# STM32L486xx register map
File version: 1.0
Registers are 32-bit, access not given, reset 0x0 unless marked. A register's access mark holds for its fields unless they carry their own. Offsets are from the block's base; [hi:lo] are bit positions.

## DAC
Base 0x40007400
0x00 CR
  [31] BWST2, [30] CEN2, [30] CAL_FLAG2, [29] DMAUDRIE2, [29] DMAUDR2, [28] DMAEN2, [27:24] MAMP2, [23:22] WAVE2, [31:20] DACC2DHR, [21:19] TSEL2, [18] TEN2, [16] EN2, [27:16] DACC2DHR, [20:16] OTRIM2, [18:16] MODE2, [25:16] THOLD2, [23:16] TREFRESH2, [15] BWST1, [14] CEN1, [14] CAL_FLAG1, [13] DMAUDRIE1, [13] DMAUDR1, [12] DMAEN1, [11:8] MAMP1, [15:8] DACC2DHR, [7:6] WAVE1, [15:4] DACC1DHR, [15:4] DACC2DHR, [15:4] DACC1DHR, [5:3] TSEL1, [2] TEN1, [1] SWTRIG2, [0] EN1, [0] SWTRIG1, [11:0] DACC1DHR, [7:0] DACC1DHR, [11:0] DACC2DHR, [7:0] DACC2DHR, [11:0] DACC1DHR, [7:0] DACC1DHR, [11:0] DACC1DOR, [11:0] DACC2DOR, [4:0] OTRIM1, [2:0] MODE1, [9:0] TSAMPLE1, [9:0] TSAMPLE2, [9:0] THOLD1, [7:0] TREFRESH1
0x04 SWTRIGR
0x08 DHR12R1
0x0C DHR12L1
0x10 DHR8R1
0x14 DHR12R2
0x18 DHR12L2
0x1C DHR8R2
0x20 DHR12RD
0x24 DHR12LD
0x28 DHR8RD
0x2C DOR1
0x30 DOR2
0x34 SR
0x38 CCR
0x3C MCR
0x40 SHSR1
0x44 SHSR2
0x48 SHHR
0x4C SHRR

## DAC1
Base 0x40007400
0x00 CR
  [31] BWST2, [30] CEN2, [30] CAL_FLAG2, [29] DMAUDRIE2, [29] DMAUDR2, [28] DMAEN2, [27:24] MAMP2, [23:22] WAVE2, [31:20] DACC2DHR, [21:19] TSEL2, [18] TEN2, [16] EN2, [27:16] DACC2DHR, [20:16] OTRIM2, [18:16] MODE2, [25:16] THOLD2, [23:16] TREFRESH2, [15] BWST1, [14] CEN1, [14] CAL_FLAG1, [13] DMAUDRIE1, [13] DMAUDR1, [12] DMAEN1, [11:8] MAMP1, [15:8] DACC2DHR, [7:6] WAVE1, [15:4] DACC1DHR, [15:4] DACC2DHR, [15:4] DACC1DHR, [5:3] TSEL1, [2] TEN1, [1] SWTRIG2, [0] EN1, [0] SWTRIG1, [11:0] DACC1DHR, [7:0] DACC1DHR, [11:0] DACC2DHR, [7:0] DACC2DHR, [11:0] DACC1DHR, [7:0] DACC1DHR, [11:0] DACC1DOR, [11:0] DACC2DOR, [4:0] OTRIM1, [2:0] MODE1, [9:0] TSAMPLE1, [9:0] TSAMPLE2, [9:0] THOLD1, [7:0] TREFRESH1
0x04 SWTRIGR
0x08 DHR12R1
0x0C DHR12L1
0x10 DHR8R1
0x14 DHR12R2
0x18 DHR12L2
0x1C DHR8R2
0x20 DHR12RD
0x24 DHR12LD
0x28 DHR8RD
0x2C DOR1
0x30 DOR2
0x34 SR
0x38 CCR
0x3C MCR
0x40 SHSR1
0x44 SHSR2
0x48 SHHR
0x4C SHRR

## OPAMP
Base 0x40007800
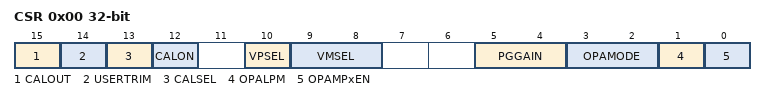
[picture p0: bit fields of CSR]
0x00 CSR
  [15] CALOUT, [14] USERTRIM, [13] CALSEL, [12] CALON, [10] VPSEL, [9:8] VMSEL, [12:8] TRIMOFFSETP, [12:8] TRIMLPOFFSETP, [5:4] PGGAIN, [3:2] OPAMODE, [1] OPALPM, [0] OPAMPxEN, [4:0] TRIMOFFSETN, [4:0] TRIMLPOFFSETN
0x04 OTR
0x08 LPOTR

## OPAMP1
Base 0x40007800
Same registers: OPAMP2 0x40007810
0x00 CSR
  [15] CALOUT, [14] USERTRIM, [13] CALSEL, [12] CALON, [10] VPSEL, [9:8] VMSEL, [12:8] TRIMOFFSETP, [12:8] TRIMLPOFFSETP, [5:4] PGGAIN, [3:2] OPAMODE, [1] OPALPM, [0] OPAMPxEN, [4:0] TRIMOFFSETN, [4:0] TRIMLPOFFSETN
0x04 OTR
0x08 LPOTR

## OPAMP12_COMMON
Base 0x40007800
0x00 CSR
  [15] CALOUT, [14] USERTRIM, [13] CALSEL, [12] CALON, [10] VPSEL, [9:8] VMSEL, [5:4] PGGAIN, [3:2] OPAMODE, [1] OPALPM, [0] OPAMPxEN

## LPTIM1
Base 0x40007C00
Same registers: LPTIM2 0x40009400
0x00 ISR
  [24] ENC, [23] COUNTMODE, [22] PRELOAD, [21] WAVPOL, [20] WAVE, [19] TIMOUT, [18:17] TRIGEN, [15:13] TRIGSEL, [11:9] PRESC, [6] DOWN, [6] DOWNCF, [6] DOWNIE, [7:6] TRGFLT, [5] UP, [5] UPCF, [5] UPIE, [4] ARROK, [4] ARROKCF, [4] ARROKIE, [3] CMPOK, [3] CMPOKCF, [3] CMPOKIE, [4:3] CKFLT, [2] EXTTRIG, [2] EXTTRIGCF, [2] EXTTRIGIE, [2] CNTSTRT, [1] ARRM, [1] ARRMCF, [1] ARRMIE, [2:1] CKPOL, [1] SNGSTRT, [0] CMPM, [0] CMPMCF, [0] CMPMIE, [0] CKSEL, [0] ENABLE, [15:0] CMP, [15:0] ARR, [15:0] CNT, [1:0] OR
0x04 ICR
0x08 IER
0x0C CFGR
0x10 CR
0x14 CMP
0x18 ARR
0x1C CNT
0x20 OR

## SWPMI1
Base 0x40008800
0x00 CR
  [10] DEACT, [10] DEACTF, [9] SUSP, [8] SRF, [8] CSRF, [8] SRIE, [7] TCF, [7] CTCF, [7] TCIE, [6] TXE, [6] TIE, [5] SWPACT, [5] RXNE, [5] RIE, [4] LPBK, [4] TXUNRF, [4] CTXUNRF, [4] TXUNRIE, [3] TXMODE, [3] RXOVRF, [3] CRXOVRF, [3] RXOVRIE, [2] RXMODE, [2] RXBERF, [2] CRXBERF, [2] RXBERIE, [1] TXDMA, [1] TXBEF, [1] CTXBEF, [1] TXBEIE, [1] CLASS, [0] RXDMA, [5:0] BR, [0] RXBFF, [0] CRXBFF, [0] RXBFIE, [1:0] RFL_0_1, [31:0] TD, [31:0] RD, [0] TBYP
0x04 BRR
0x0C ISR
0x10 ICR
0x14 IER
0x18 RFL
0x1C TDR
0x20 RDR
0x24 OR
